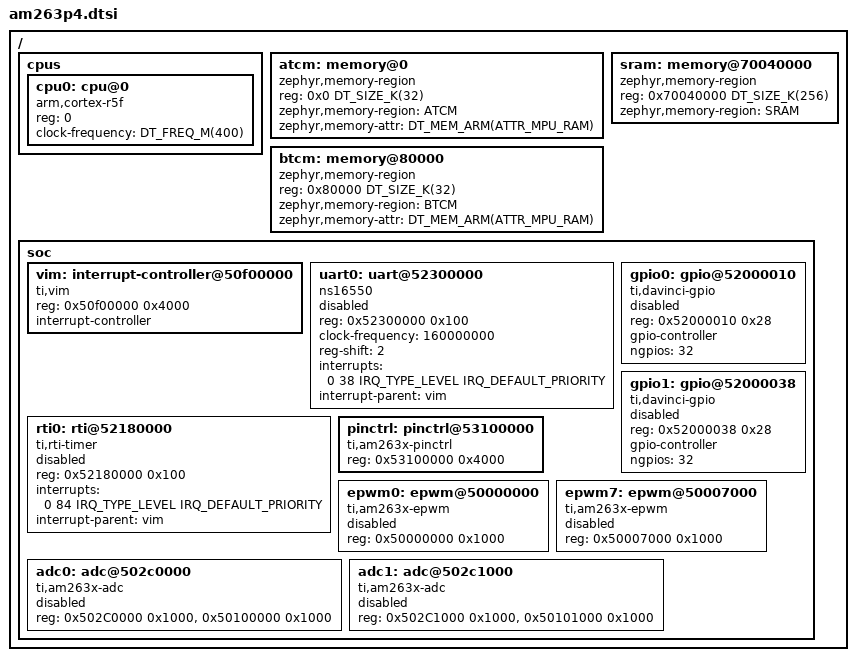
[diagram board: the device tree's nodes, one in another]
/*
 * Copyright (c) 2026
 *
 * SPDX-License-Identifier: Apache-2.0
 *
 * TI AM263P4 SoC devicetree (Cortex-R5F view).
 *
 * Addresses and interrupt numbers are taken from the TI MCU+ SDK
 * (mcupsdk-core) for am263px and the AM263Px TRM (SPRUJ55):
 *   - peripheral bases:  cslr_soc_baseaddress.h
 *   - R5FSS0/core0 IRQs: cslr_intr_r5fss0_core0.h
 *   - memory layout:     board-tested SDK linker (R5FSS0 core0)
 * See docs/am263p-memory-map.md.
 */

#include <mem.h>
#include <freq.h>
#include <arm/armv7-r.dtsi>
#include <zephyr/dt-bindings/memory-attr/memory-attr-arm.h>
#include <zephyr/dt-bindings/interrupt-controller/ti-vim.h>

/ {
	#address-cells = <1>;
	#size-cells = <1>;

	cpus {
		#address-cells = <1>;
		#size-cells = <0>;

		cpu0: cpu@0 {
			device_type = "cpu";
			compatible = "arm,cortex-r5f";
			reg = <0>;
			clock-frequency = <DT_FREQ_M(400)>;
		};
	};

	/* R5FSS0 Core0 local TCM (ATCM at 0x0, BTCM at 0x80000). */
	atcm: memory@0 {
		device_type = "memory";
		compatible = "zephyr,memory-region", "mmio-sram";
		reg = <0x0 DT_SIZE_K(32)>;
		zephyr,memory-region = "ATCM";
		zephyr,memory-attr = <DT_MEM_ARM(ATTR_MPU_RAM)>;
	};

	btcm: memory@80000 {
		device_type = "memory";
		compatible = "zephyr,memory-region", "mmio-sram";
		reg = <0x80000 DT_SIZE_K(32)>;
		zephyr,memory-region = "BTCM";
		zephyr,memory-attr = <DT_MEM_ARM(ATTR_MPU_RAM)>;
	};

	/*
	 * Main RAM: this core's non-overlapping 256 KB slice of L2OCRAM,
	 * matching TI's tested single-core layout (OCRAM @ 0x70040000).
	 */
	sram: memory@70040000 {
		compatible = "zephyr,memory-region", "mmio-sram";
		reg = <0x70040000 DT_SIZE_K(256)>;
		zephyr,memory-region = "SRAM";
	};

	soc {
		/* VIM — Vectored Interrupt Manager (base 0x50F00000). */
		vim: interrupt-controller@50f00000 {
			#address-cells = <1>;
			compatible = "ti,vim";
			reg = <0x50f00000 0x4000>;
			interrupt-controller;
			/* {IRQ/FIQ, IRQ_NUM, IRQ_TYPE, IRQ_PRIO} */
			#interrupt-cells = <4>;
		};

		/* UART0 — console (XDS110 USB-UART on the LaunchPad). */
		uart0: uart@52300000 {
			compatible = "ns16550";
			reg = <0x52300000 0x100>;
			/*
			 * UART module functional clock.
			 * Measured on TMDSCNCD263P ControlCARD (gel): 160 MHz.
			 * Previously assumed 96 MHz (SysConfig default on LaunchPad).
			 * Update this if your board shows a different value.
			 */
			clock-frequency = <160000000>;
			reg-shift = <2>;
			interrupts = <0 38 IRQ_TYPE_LEVEL IRQ_DEFAULT_PRIORITY>;
			interrupt-parent = <&vim>;
			status = "disabled";
		};

		/* RTI0 — system tick source (compare interrupt 0 = VIM IRQ 84). */
		rti0: rti@52180000 {
			compatible = "ti,rti-timer";
			reg = <0x52180000 0x100>;
			interrupts = <0 84 IRQ_TYPE_LEVEL IRQ_DEFAULT_PRIORITY>;
			interrupt-parent = <&vim>;
			status = "disabled";
		};

		/*
		 * GPIO0 instance (R5FSS0-core0), peripheral base 0x52000000.
		 * Per TRM SPRUJ55 §13.1.1 a single GPIO instance covers all GPIO
		 * signals through banked register *pairs* (GPIO_*_DATA01 for
		 * signals 0..31, GPIO_*_DATA23 for 32..63, ...). The generic
		 * "ti,davinci-gpio" driver is a flat 32-pin-per-node model whose
		 * register struct starts at DIR, so each node's `reg` points at
		 * one bank pair's DIR register:
		 *   gpio0 -> bank01 DIR @ +0x10 -> GPIO signals 0..31
		 *   gpio1 -> bank23 DIR @ +0x38 -> GPIO signals 32..63
		 * DIR/OUT_DATA/SET_DATA/CLR_DATA offsets are verified (CLAUDE.md,
		 * from SDK gpio.h). The in_data/trigger registers in the driver
		 * struct are NOT yet TRM-verified — correct for OUTPUT use; must
		 * be confirmed before relying on GPIO input or interrupts.
		 * Boards enable the bank(s) they use.
		 */
		gpio0: gpio@52000010 {
			compatible = "ti,davinci-gpio";
			reg = <0x52000010 0x28>;
			gpio-controller;
			#gpio-cells = <2>;
			ngpios = <32>;
			status = "disabled";
		};

		gpio1: gpio@52000038 {
			compatible = "ti,davinci-gpio";
			reg = <0x52000038 0x28>;
			gpio-controller;
			#gpio-cells = <2>;
			ngpios = <32>;
			status = "disabled";
		};

		/*
		 * IOMUX pad-config block (PADCONFIG registers, base 0x53100000).
		 * Individual pads are described in board files via child nodes
		 * carrying a "pinmux = <reg val>" pair; the AM263x pinctrl driver
		 * writes val to the absolute reg. The controller needs no addressing
		 * of its own, so it has no #address-cells.
		 */
pinctrl: pinctrl@53100000 {
	compatible = "ti,am263x-pinctrl";
	reg = <0x53100000 0x4000>;
};

/* ePWM controller instances (used for LED brightness via PWM driver).
 * Real bases from the user's MCU+ SDK (cslr_soc_baseaddress.h):
 *   CSL_CONTROLSS_G0_EPWM0_U_BASE = 0x50000000
 *   CSL_CONTROLSS_G0_EPWM7_U_BASE = 0x50007000
 */
epwm0: epwm@50000000 {
	compatible = "ti,am263x-epwm";
	reg = <0x50000000 0x1000>;
	#pwm-cells = <3>;
	status = "disabled";
};

epwm7: epwm@50007000 {
	compatible = "ti,am263x-epwm";
	reg = <0x50007000 0x1000>;
	#pwm-cells = <3>;
	status = "disabled";
};

/*
 * ADC instances (Type 4 SAR) in CONTROLSS.
 * Bases from MCU+ SDK cslr_soc_baseaddress.h (verified):
 *   ADC0 cfg @ 0x502C0000, result @ 0x50100000 (similar stride for ADC1-4).
 * Separate windows: cfg for SOC/CTL/INT config, result for ADCRESULTx (16x 16-bit).
 * Clock: shares the CONTROLSS source clock (already enabled in soc.c for ePWM).
 * Reference: may require SOC_enableAdc*Reference() from SDK soc.c (TOP_CTRL refbuf)
 * or external VREF on board; UNVERIFIED for ControlCARD until tested.
 * Interrupts: 4x ADCINT per module + PPB/OSINT events, routed via
 * CONTROLSS_INTRXBAR0 -> VIM input line (see TRM 7.5.2.13 + 10.3/10.4).
 * For initial software-triggered polling use, interrupts property is omitted.
 * DT node uses two reg entries (cfg, result) per instance.
 */
adc0: adc@502c0000 {
	compatible = "ti,am263x-adc";
	reg = <0x502C0000 0x1000>, <0x50100000 0x1000>;
	#io-channel-cells = <1>;
	status = "disabled";
};

adc1: adc@502c1000 {
	compatible = "ti,am263x-adc";
	reg = <0x502C1000 0x1000>, <0x50101000 0x1000>;
	#io-channel-cells = <1>;
	status = "disabled";
};
};
};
